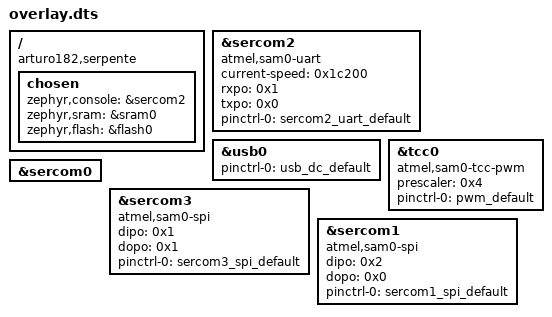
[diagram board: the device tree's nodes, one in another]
/ {
	compatible = "arturo182,serpente";
	chosen {
		zephyr,console = &sercom2;
		zephyr,sram = &sram0;
		zephyr,flash = &flash0;
	};
};
&sercom2{
	compatible = "atmel,sam0-uart";
	status = "okay";
	current-speed = < 0x1c200 >;
	rxpo = < 0x1 >;
	txpo = < 0x0 >;
	pinctrl-0 = < &sercom2_uart_default >;
	pinctrl-names = "default";
};
&usb0{
	status = "okay";
	pinctrl-0 = < &usb_dc_default >;
	pinctrl-names = "default";
};
&tcc0{
	compatible = "atmel,sam0-tcc-pwm";
	status = "okay";
	prescaler = < 0x4 >;
	#pwm-cells = < 0x2 >;
	pinctrl-0 = < &pwm_default >;
	pinctrl-names = "default";
};
&sercom0{
	status = "okay";
};
&sercom3{
	compatible = "atmel,sam0-spi";
	status = "okay";
	dipo = < 0x1 >;
	dopo = < 0x1 >;
	#address-cells = < 0x1 >;
	#size-cells = < 0x0 >;
	pinctrl-0 = < &sercom3_spi_default >;
	pinctrl-names = "default";
};
&sercom1{
	compatible = "atmel,sam0-spi";
	status = "okay";
	dipo = < 0x2 >;
	dopo = < 0x0 >;
	#address-cells = < 0x1 >;
	#size-cells = < 0x0 >;
	pinctrl-0 = < &sercom1_spi_default >;
	pinctrl-names = "default";
};
